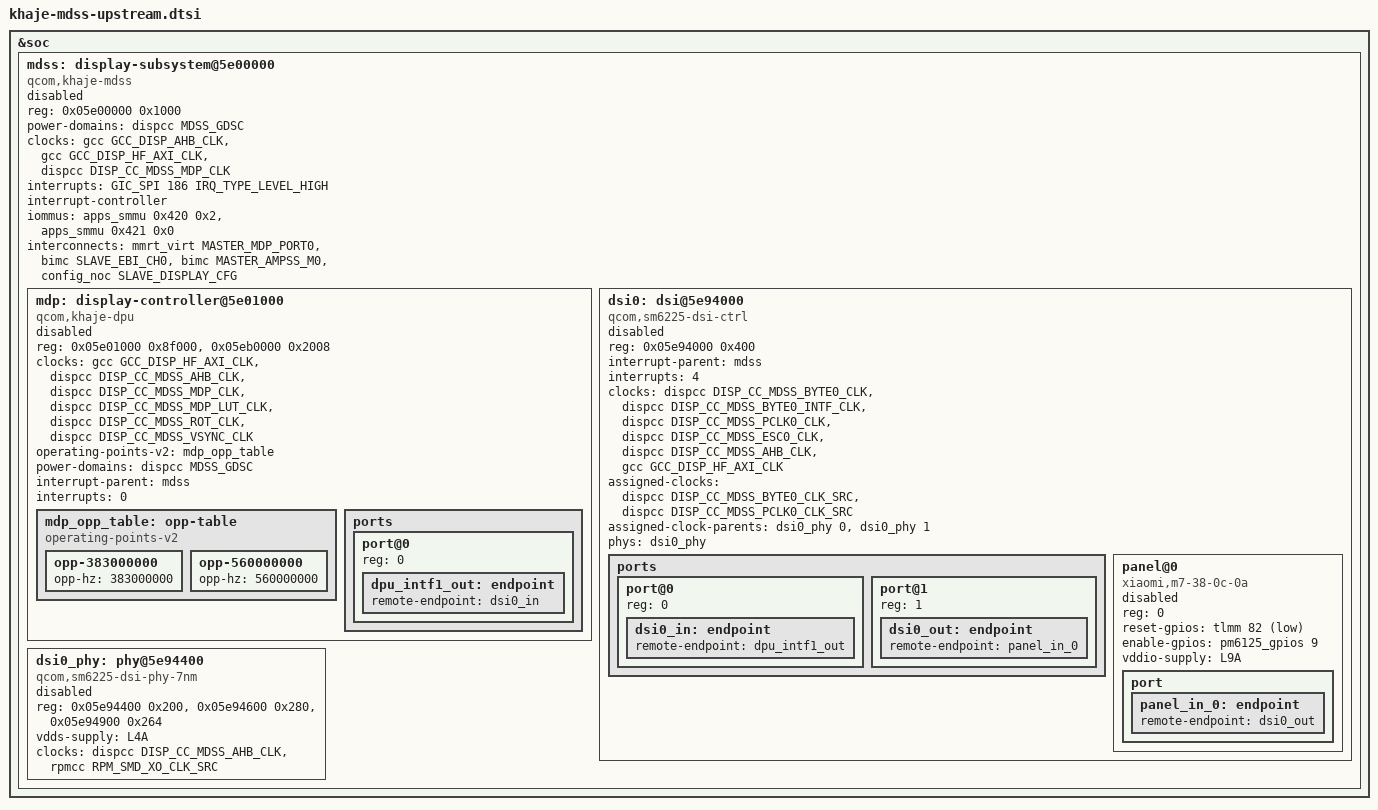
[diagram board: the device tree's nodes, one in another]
/* SPDX-License-Identifier: GPL-2.0-only */
/*
 * DTS DE TESTE — hierarquia upstream MDSS pai + DPU filho para Khaje.
 *
 * NAO e incluido por nenhuma DTS de producao e nao e encenado por
 * tools/integrate_dts.py (que so copia device-tree/source). Serve para
 * validar estaticamente o contrato de reg/IRQ/clocks/ICC/IOMMU dos
 * bindings qcom,khaje-mdss / qcom,khaje-dpu (patch 0018) contra as
 * labels reais da arvore encenada, sem ativar probe no Topaz.
 *
 * Uso manual: incluir depois de khaje-idp-nopmi.dtsi numa DTS de teste
 * e compilar com tools/build_dts.py / dtc. Os nos ficam "disabled".
 *
 * Recursos reconciliados com o FDT ativo (qcom,mdss_mdp/qcom,sde-kms):
 *   - reg MDSS 0x5e00000, MDP 0x5e01000 (sde-off 0x1000), VBIF
 *     0x5eb0000 tamanho 0x2008;
 *   - IRQ do MDSS: GIC SPI 186;
 *   - iommus apps_smmu 0x420/0x421;
 *   - ICC: mmrt_virt MASTER_MDP_PORT0 -> bimc SLAVE_EBI_CH0 (dados) e
 *     bimc MASTER_AMPSS_M0 -> config_noc SLAVE_DISPLAY_CFG (reg);
 *   - clocks GCC DISP AHB/HF_AXI e DISPCC MDP/AHB/LUT/ROT/VSYNC,
 *     taxas de core 383/560 MHz de khaje-sde.dtsi.
 *
 * Bloqueios conhecidos antes de qualquer ativacao:
 *   - o GDSC do MDSS passou a ser registrado pelo dispcc-khaje (patch
 *     0019, gdscr 0x1004), mas ainda sem validacao em hardware e sem
 *     remover o no vendor mdss_core_gdsc, que nao pode coexistir com
 *     esta hierarquia numa ativacao real;
 *   - filho DSI/PHY e painel M7 ainda nao modelados neste fragmento;
 *   - opp-table sem required-opps ate o contrato de corner (RPMPD vs.
 *     votos RPM-SMD do clk-vdd-class) ser fechado.
 */

#include <dt-bindings/clock/qcom,gcc-khaje.h>
#include <dt-bindings/clock/qcom,rpmcc.h>
#include <dt-bindings/clock/qcom,dispcc-khaje.h>
#include <dt-bindings/interconnect/qcom,bengal.h>
#include <dt-bindings/interrupt-controller/arm-gic.h>

&soc {
	mdss: display-subsystem@5e00000 {
		compatible = "qcom,khaje-mdss";
		reg = <0x05e00000 0x1000>;
		reg-names = "mdss";

		power-domains = <&dispcc MDSS_GDSC>;

		clocks = <&gcc GCC_DISP_AHB_CLK>,
			 <&gcc GCC_DISP_HF_AXI_CLK>,
			 <&dispcc DISP_CC_MDSS_MDP_CLK>;

		interrupts = <GIC_SPI 186 IRQ_TYPE_LEVEL_HIGH>;
		interrupt-controller;
		#interrupt-cells = <1>;

		iommus = <&apps_smmu 0x420 0x2>,
			 <&apps_smmu 0x421 0x0>;

		interconnects = <&mmrt_virt MASTER_MDP_PORT0
				 &bimc SLAVE_EBI_CH0>,
				<&bimc MASTER_AMPSS_M0
				 &config_noc SLAVE_DISPLAY_CFG>;
		interconnect-names = "mdp0-mem", "cpu-cfg";

		ranges;
		#address-cells = <1>;
		#size-cells = <1>;

		status = "disabled";

		mdp: display-controller@5e01000 {
			compatible = "qcom,khaje-dpu";
			reg = <0x05e01000 0x8f000>,
			      <0x05eb0000 0x2008>;
			reg-names = "mdp", "vbif";

			clocks = <&gcc GCC_DISP_HF_AXI_CLK>,
				 <&dispcc DISP_CC_MDSS_AHB_CLK>,
				 <&dispcc DISP_CC_MDSS_MDP_CLK>,
				 <&dispcc DISP_CC_MDSS_MDP_LUT_CLK>,
				 <&dispcc DISP_CC_MDSS_ROT_CLK>,
				 <&dispcc DISP_CC_MDSS_VSYNC_CLK>;
			clock-names = "bus", "iface", "core",
				      "lut", "rot", "vsync";

			operating-points-v2 = <&mdp_opp_table>;
			power-domains = <&dispcc MDSS_GDSC>;

			interrupt-parent = <&mdss>;
			interrupts = <0>;

			status = "disabled";

			mdp_opp_table: opp-table {
				compatible = "operating-points-v2";

				opp-383000000 {
					opp-hz = /bits/ 64 <383000000>;
				};

				opp-560000000 {
					opp-hz = /bits/ 64 <560000000>;
				};
			};

			ports {
				#address-cells = <1>;
				#size-cells = <0>;

				port@0 {
					reg = <0>;
					dpu_intf1_out: endpoint {
						remote-endpoint = <&dsi0_in>;
					};
				};
			};
		};

		/* DSI 6G v2.4: cfg upstream ja contem io_start 0x5e94000 */
		dsi0: dsi@5e94000 {
			compatible = "qcom,sm6225-dsi-ctrl",
				     "qcom,mdss-dsi-ctrl";
			reg = <0x05e94000 0x400>;
			reg-names = "dsi_ctrl";

			interrupt-parent = <&mdss>;
			interrupts = <4>;

			clocks = <&dispcc DISP_CC_MDSS_BYTE0_CLK>,
				 <&dispcc DISP_CC_MDSS_BYTE0_INTF_CLK>,
				 <&dispcc DISP_CC_MDSS_PCLK0_CLK>,
				 <&dispcc DISP_CC_MDSS_ESC0_CLK>,
				 <&dispcc DISP_CC_MDSS_AHB_CLK>,
				 <&gcc GCC_DISP_HF_AXI_CLK>;
			clock-names = "byte", "byte_intf", "pixel",
				      "core", "iface", "bus";

			assigned-clocks = <&dispcc DISP_CC_MDSS_BYTE0_CLK_SRC>,
					  <&dispcc DISP_CC_MDSS_PCLK0_CLK_SRC>;
			assigned-clock-parents = <&dsi0_phy 0>, <&dsi0_phy 1>;

			phys = <&dsi0_phy>;

			#address-cells = <1>;
			#size-cells = <0>;

			status = "disabled";

			ports {
				#address-cells = <1>;
				#size-cells = <0>;

				port@0 {
					reg = <0>;
					dsi0_in: endpoint {
						remote-endpoint = <&dpu_intf1_out>;
					};
				};

				port@1 {
					reg = <1>;
					dsi0_out: endpoint {
						remote-endpoint = <&panel_in_0>;
					};
				};
			};

			/* Painel ativo do aparelho: M7 _0a (patch 0021) */
			panel@0 {
				compatible = "xiaomi,m7-38-0c-0a";
				reg = <0>;

				reset-gpios = <&tlmm 82 GPIO_ACTIVE_LOW>;
				enable-gpios = <&pm6125_gpios 9 GPIO_ACTIVE_HIGH>;
				vddio-supply = <&L9A>;

				status = "disabled";

				port {
					panel_in_0: endpoint {
						remote-endpoint = <&dsi0_out>;
					};
				};
			};
		};

		/* PHY 7nm geracao v4.1 (FDT: qcom,dsi-phy-v4.1) */
		dsi0_phy: phy@5e94400 {
			compatible = "qcom,sm6225-dsi-phy-7nm";
			reg = <0x05e94400 0x200>,
			      <0x05e94600 0x280>,
			      <0x05e94900 0x264>;
			reg-names = "dsi_phy", "dsi_phy_lane", "dsi_pll";

			#clock-cells = <1>;
			#phy-cells = <0>;

			vdds-supply = <&L4A>;
			clocks = <&dispcc DISP_CC_MDSS_AHB_CLK>,
				 <&rpmcc RPM_SMD_XO_CLK_SRC>;
			clock-names = "iface", "ref";

			status = "disabled";
		};
	};
};
